# SN32F700 register map
Vendor: SONiX Technology Co., Ltd.; Series: SN32F700; File version: 1.9
CPU: CM0 r0p0, little endian, no MPU, no FPU, 2 interrupt priority bits
Registers are 32-bit, read-write, reset 0x0 unless marked. A register's access mark holds for its fields unless they carry their own. Offsets are from the block's base; [hi:lo] are bit positions; {n}, {i} and the like mark numbered series.

## SN_I2S — I2S
Base 0x4001A000
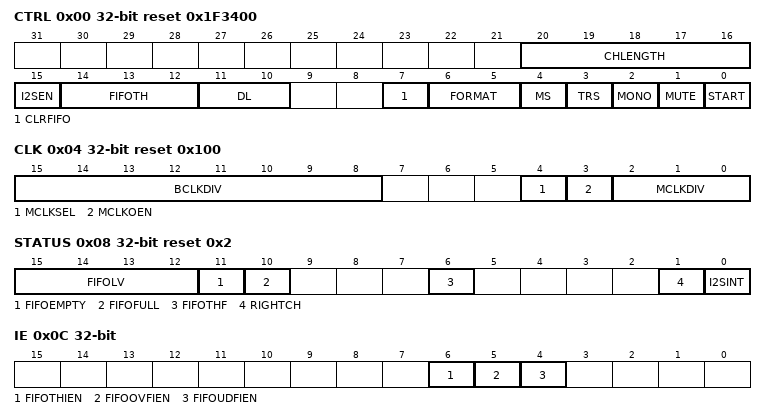
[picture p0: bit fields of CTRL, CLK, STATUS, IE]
0x00 CTRL reset 0x1F3400 — Offset:0x00 I2S Control Register
  [20:16] CHLENGTH — Bit number of single channel
    {v}={v+1} bits (v=7..30); 31=32 bits (Max)
  [15] I2SEN — I2S enable
    0=Disable I2S; 1=Enable I2S
  [14:12] FIFOTH — FIFO threshold level
    {v}=FIFO threshold level={v} (v=0..7)
  [11:10] DL — Data length
    0=Data length=8 bits; 1=Data length=16 bits; 2=Data length=24 bits; 3=Data length=32 bits
  [7] CLRFIFO wo — Clear I2S FIFO
    0=No effect; 1=Clear (Reset FIFO)
  [6:5] FORMAT — I2S format
    0=Standard I2S format; 1=Left-justified format; 2=Right(MSB)-justified format
  [4] MS — Master/slave selection
    0=Master; 1=Slave
  [3] TRS — Transmitter/receiver selection
    0=Transmitter; 1=Receiver
  [2] MONO — Mono/stereo selection
    0=Stereo mode; 1=Mono mode
  [1] MUTE — Mute enable
    0=Disable mute; 1=Enable mute (I2SSDA output is 0)
  [0] START — Start Transmit/Receive
    0=Stop transmit/receive; 1=Start transmit/receive
0x04 CLK reset 0x100 — Offset:0x04 I2S Clock Register
  [15:8] BCLKDIV — BCLK divider
  [4] MCLKSEL — MLCK source selection
    0=I2S_PCLK (MCLK source of master is from I2S_PCLK); 1=GPIO (MCLK source of master is from GPIO)
  [3] MCLKOEN — MLCK output enable
    0=Disable MCLK output; 1=Enable MCLK output
  [2:0] MCLKDIV — MCLK divider
    0=MCLK=MCLK source; 1=MCLK=MCLK source/2; 2=MCLK=MCLK source/4; 3=MCLK=MCLK source/6; 4=MCLK=MCLK source/8; 5=MCLK=MCLK source/10; 6=MCLK=MCLK source/12; 7=MCLK=MCLK source/14
0x08 STATUS ro reset 0x2 — Offset:0x08 I2S Status Register
  [15:12] FIFOLV — FIFO used level
    0=0/8 FIFO is used (Empty); 1=1/8 FIFO is used; 2=2/8 FIFO is used (Empty); 3=3/8 FIFO is used; 4=4/8 FIFO is used (Empty); 5=5/8 FIFO is used; 6=6/8 FIFO is used (Empty); 7=7/8 FIFO is used; 8=8/8 FIFO is used (Full)
  [11] FIFOEMPTY — FIFO empty flag
    0=Not empty (FIFO is not empty); 1=Empty (FIFO is empty)
  [10] FIFOFULL — FIFO full flag
    0=Not full (FIFO is not full); 1=Full (FIFO is full)
  [6] FIFOTHF — FIFO threshold flag
    0=FIFOLV is larger equal than FIFOTH as transmitter, FIFOLV is less equal than FIFOTH as receiver; 1=FIFOLV is less than FIFOTH as transmitter, FIFOLV is larger than FIFOTH as receiver
  [1] RIGHTCH — Current channel status
    0=Left (Current channel is left channel); 1=Right (Current channel is right channel)
  [0] I2SINT — I2S interrupt flag
    0=No (No I2S interrupt); 1=I2S interrupt occurs
0x0C IE — Offset:0x0C I2S Interrupt Enable Register
  [6] FIFOTHIEN — FIFO threshold interrupt enable
    0=Disable FIFO threshold interrupt; 1=Enable FIFO threshold interrupt
  [5] FIFOOVFIEN — FIFO overflow interrupt enable
    0=Disable FIFO overflow interrupt; 1=Enable FIFO overflow interrupt
  [4] FIFOUDFIEN — FIFO underflow interrupt enable
    0=Disable FIFO underflow interrupt; 1=Enable FIFO underflow interrupt
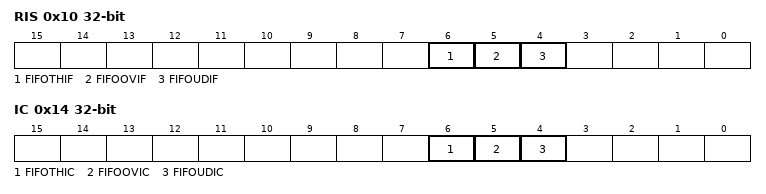
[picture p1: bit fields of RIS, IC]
0x10 RIS ro — Offset:0x10 I2S Raw Interrupt Status Register
  [6] FIFOTHIF — FIFO threshold interrupt flag
    0=No FIFO threshold interrupt; 1=FIFO threshold triggered (FIFO threshold interrupt)
  [5] FIFOOVIF — FIFO overflow interrupt flag
    0=No FIFO overflow; 1=FIFO overflow
  [4] FIFOUDIF — FIFO underflow interrupt flag
    0=No FIFO underflow; 1=FIFO underflow
0x14 IC wo — Offset:0x14 I2S Interrupt Clear Register
  [6] FIFOTHIC — FIFO threshold interrupt clear
    0=No effect; 1=Clear FIFOTHIF bit
  [5] FIFOOVIC — FIFO overflow interrupt clear
    0=No effect; 1=Clear FIFOOVIF bit
  [4] FIFOUDIC — FIFO underflow interrupt clear
    0=No effect; 1=Clear FIFOUDIF bit
0x18 FIFO — Offset:0x18 I2S FIFO Register
